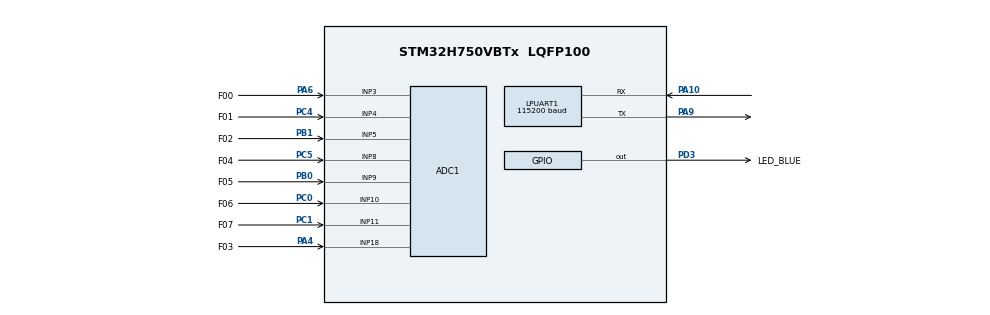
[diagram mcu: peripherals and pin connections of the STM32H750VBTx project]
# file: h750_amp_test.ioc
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ADC1.Channel-0\#ChannelRegularConversion=ADC_CHANNEL_3
ADC1.Channel-1\#ChannelRegularConversion=ADC_CHANNEL_4
ADC1.Channel-2\#ChannelRegularConversion=ADC_CHANNEL_5
ADC1.Channel-3\#ChannelRegularConversion=ADC_CHANNEL_8
ADC1.Channel-4\#ChannelRegularConversion=ADC_CHANNEL_9
ADC1.Channel-5\#ChannelRegularConversion=ADC_CHANNEL_10
ADC1.Channel-6\#ChannelRegularConversion=ADC_CHANNEL_11
ADC1.Channel-7\#ChannelRegularConversion=ADC_CHANNEL_18
ADC1.ClockPrescaler=ADC_CLOCK_ASYNC_DIV8
ADC1.ContinuousConvMode=ENABLE
ADC1.ConversionDataManagement=ADC_CONVERSIONDATA_DMA_CIRCULAR
ADC1.NbrOfConversion=8
ADC1.NbrOfConversionFlag=1
ADC1.OffsetNumber-0\#ChannelRegularConversion=ADC_OFFSET_NONE
ADC1.OffsetNumber-1\#ChannelRegularConversion=ADC_OFFSET_NONE
ADC1.OffsetNumber-2\#ChannelRegularConversion=ADC_OFFSET_NONE
ADC1.OffsetNumber-3\#ChannelRegularConversion=ADC_OFFSET_NONE
ADC1.OffsetNumber-4\#ChannelRegularConversion=ADC_OFFSET_NONE
ADC1.OffsetNumber-5\#ChannelRegularConversion=ADC_OFFSET_NONE
ADC1.OffsetNumber-6\#ChannelRegularConversion=ADC_OFFSET_NONE
ADC1.OffsetNumber-7\#ChannelRegularConversion=ADC_OFFSET_NONE
ADC1.OffsetSignedSaturation-0\#ChannelRegularConversion=DISABLE
ADC1.OffsetSignedSaturation-1\#ChannelRegularConversion=DISABLE
ADC1.OffsetSignedSaturation-2\#ChannelRegularConversion=DISABLE
ADC1.OffsetSignedSaturation-3\#ChannelRegularConversion=DISABLE
ADC1.OffsetSignedSaturation-4\#ChannelRegularConversion=DISABLE
ADC1.OffsetSignedSaturation-5\#ChannelRegularConversion=DISABLE
ADC1.OffsetSignedSaturation-6\#ChannelRegularConversion=DISABLE
ADC1.OffsetSignedSaturation-7\#ChannelRegularConversion=DISABLE
ADC1.Rank-0\#ChannelRegularConversion=1
ADC1.Rank-1\#ChannelRegularConversion=2
ADC1.Rank-2\#ChannelRegularConversion=3
ADC1.Rank-3\#ChannelRegularConversion=4
ADC1.Rank-4\#ChannelRegularConversion=5
ADC1.Rank-5\#ChannelRegularConversion=6
ADC1.Rank-6\#ChannelRegularConversion=7
ADC1.Rank-7\#ChannelRegularConversion=8
ADC1.SamplingTime-0\#ChannelRegularConversion=ADC_SAMPLETIME_32CYCLES_5
ADC1.SamplingTime-1\#ChannelRegularConversion=ADC_SAMPLETIME_32CYCLES_5
ADC1.SamplingTime-2\#ChannelRegularConversion=ADC_SAMPLETIME_32CYCLES_5
ADC1.SamplingTime-3\#ChannelRegularConversion=ADC_SAMPLETIME_32CYCLES_5
ADC1.SamplingTime-4\#ChannelRegularConversion=ADC_SAMPLETIME_32CYCLES_5
ADC1.SamplingTime-5\#ChannelRegularConversion=ADC_SAMPLETIME_32CYCLES_5
ADC1.SamplingTime-6\#ChannelRegularConversion=ADC_SAMPLETIME_32CYCLES_5
ADC1.SamplingTime-7\#ChannelRegularConversion=ADC_SAMPLETIME_32CYCLES_5
ADC1.master=1
Dma.ADC1.0.Direction=DMA_PERIPH_TO_MEMORY
Dma.ADC1.0.EventEnable=DISABLE
Dma.ADC1.0.FIFOMode=DMA_FIFOMODE_DISABLE
Dma.ADC1.0.Instance=DMA1_Stream0
Dma.ADC1.0.MemDataAlignment=DMA_MDATAALIGN_WORD
Dma.ADC1.0.MemInc=DMA_MINC_ENABLE
Dma.ADC1.0.Mode=DMA_CIRCULAR
Dma.ADC1.0.PeriphDataAlignment=DMA_PDATAALIGN_WORD
Dma.ADC1.0.PeriphInc=DMA_PINC_DISABLE
Dma.ADC1.0.Polarity=HAL_DMAMUX_REQ_GEN_RISING
Dma.ADC1.0.Priority=DMA_PRIORITY_LOW
Dma.ADC1.0.RequestNumber=1
Dma.ADC1.0.SignalID=NONE
Dma.ADC1.0.SyncEnable=DISABLE
Dma.ADC1.0.SyncPolarity=HAL_DMAMUX_SYNC_NO_EVENT
Dma.ADC1.0.SyncRequestNumber=1
Dma.ADC1.0.SyncSignalID=NONE
Dma.Request0=ADC1
LPUART1.BaudRate=115200
Mcu.Family=STM32H7
Mcu.Name=STM32H750VBTx
Mcu.Package=LQFP100
NVIC.ADC_IRQn=true\:0\:0\:false\:false\:true\:true\:true\:true
NVIC.DMA1_Stream0_IRQn=true\:0\:0\:false\:false\:true\:false\:true\:true
NVIC.PriorityGroup=NVIC_PRIORITYGROUP_4
PA10.Mode=Asynchronous
PA10.Signal=LPUART1_RX
PA13\ (JTMS/SWDIO).Mode=Serial_Wire
PA13\ (JTMS/SWDIO).Signal=DEBUG_JTMS-SWDIO
PA14\ (JTCK/SWCLK).Mode=Serial_Wire
PA14\ (JTCK/SWCLK).Signal=DEBUG_JTCK-SWCLK
PA4.GPIO_Label=F03
PA4.Signal=ADCx_INP18
PA6.GPIO_Label=F00
PA6.Signal=ADCx_INP3
PA9.Mode=Asynchronous
PA9.Signal=LPUART1_TX
PB0.GPIO_Label=F05
PB0.Signal=ADCx_INP9
PB1.GPIO_Label=F02
PB1.Signal=ADCx_INP5
PC0.GPIO_Label=F06
PC0.Signal=ADCx_INP10
PC1.GPIO_Label=F07
PC1.Signal=ADCx_INP11
PC14-OSC32_IN\ (OSC32_IN).Mode=LSE-External-Oscillator
PC14-OSC32_IN\ (OSC32_IN).Signal=RCC_OSC32_IN
PC15-OSC32_OUT\ (OSC32_OUT).Mode=LSE-External-Oscillator
PC15-OSC32_OUT\ (OSC32_OUT).Signal=RCC_OSC32_OUT
PC4.GPIO_Label=F01
PC4.Signal=ADCx_INP4
PC5.GPIO_Label=F04
PC5.Signal=ADCx_INP8
PD3.GPIO_Label=LED_BLUE
PD3.Signal=GPIO_Output
PH0-OSC_IN\ (PH0).Mode=HSE-External-Oscillator
PH0-OSC_IN\ (PH0).Signal=RCC_OSC_IN
PH1-OSC_OUT\ (PH1).Mode=HSE-External-Oscillator
PH1-OSC_OUT\ (PH1).Signal=RCC_OSC_OUT
ProjectManager.HeapSize=0x200
ProjectManager.StackSize=0x400
ProjectManager.TargetToolchain=STM32CubeIDE
RCC.ADCFreq_Value=50000000
RCC.APB1Freq_Value=50000000
RCC.APB2Freq_Value=50000000
RCC.APB3Freq_Value=50000000
RCC.APB4Freq_Value=50000000
RCC.CortexFreq_Value=400000000
RCC.D1PPRE=RCC_APB3_DIV2
RCC.D2PPRE1=RCC_APB1_DIV2
RCC.D2PPRE2=RCC_APB2_DIV2
RCC.D3PPRE=RCC_APB4_DIV2
RCC.DIVM1=5
RCC.DIVM2=25
RCC.DIVM3=25
RCC.DIVN1=160
RCC.DIVN2=200
RCC.DIVN3=200
RCC.DIVP2=4
RCC.HCLKFreq_Value=100000000
RCC.HPRE=RCC_HCLK_DIV4
RCC.PLLSourceVirtual=RCC_PLLSOURCE_HSE
RCC.SYSCLKFreq_VALUE=400000000
RCC.SYSCLKSource=RCC_SYSCLKSOURCE_PLLCLK
RCC.USBFreq_Value=400000000
SH.ADCx_INP10.0=ADC1_INP10,IN10-Single-Ended
SH.ADCx_INP11.0=ADC1_INP11,IN11-Single-Ended
SH.ADCx_INP18.0=ADC1_INP18,IN18-Single-Ended
SH.ADCx_INP3.0=ADC1_INP3,IN3-Single-Ended
SH.ADCx_INP4.0=ADC1_INP4,IN4-Single-Ended
SH.ADCx_INP5.0=ADC1_INP5,IN5-Single-Ended
SH.ADCx_INP8.0=ADC1_INP8,IN8-Single-Ended
SH.ADCx_INP9.0=ADC1_INP9,IN9-Single-Ended
board=custom

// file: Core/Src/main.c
/* USER CODE BEGIN Header */
/**
  ******************************************************************************
  * @file           : main.c
  * @brief          : Main program body
  ******************************************************************************
  * @attention
  *
  * Copyright (c) 2023 STMicroelectronics.
  * All rights reserved.
  *
  * This software is licensed under terms that can be found in the LICENSE file
  * in the root directory of this software component.
  * If no LICENSE file comes with this software, it is provided AS-IS.
  *
  ******************************************************************************
  */
/* USER CODE END Header */
#include "main.h"

ADC_HandleTypeDef hadc1;
DMA_HandleTypeDef hdma_adc1;

UART_HandleTypeDef hlpuart1;

/* USER CODE BEGIN PV */
uint32_t force_raw[8];
/* USER CODE END PV */

void SystemClock_Config(void);
static void MX_GPIO_Init(void);
static void MX_DMA_Init(void);
static void MX_LPUART1_UART_Init(void);
static void MX_ADC1_Init(void);

/* USER CODE BEGIN 0 */

void force_test(){
	float force[8];
	for(uint8_t i=0;i<8;++i){
		force[i]=(float)force_raw[i]*3.3/0xFFFF;
	}
	char msg[100]={0};
	sprintf(msg,"Force: %0.2f,%0.2f,%0.2f,%0.2f,%0.2f,%0.2f,%0.2f,%0.2f\n",force[0],force[1],force[2],force[3],force[4],force[5],force[6],force[7]);
	uint8_t i=0;
	while(msg[i]!=0 && i<100){
		HAL_UART_Transmit(&hlpuart1, (uint8_t*)(&msg[i++]), 1, 1);
	}
}

/* USER CODE END 0 */

int main(void)
{

  /* MCU Configuration--------------------------------------------------------*/

  /* Reset of all peripherals, Initializes the Flash interface and the Systick. */
  HAL_Init();

  /* Configure the system clock */
  SystemClock_Config();

  /* Initialize all configured peripherals */
  MX_GPIO_Init();
  MX_DMA_Init();
  MX_LPUART1_UART_Init();
  MX_ADC1_Init();
  /* USER CODE BEGIN 2 */

  HAL_ADC_Start_DMA(&hadc1,force_raw,8);

  /* USER CODE END 2 */

  /* Infinite loop */
  /* USER CODE BEGIN WHILE */
  while (1)
  {
	  force_test();
	  HAL_GPIO_TogglePin(LED_BLUE_GPIO_Port, LED_BLUE_Pin);
	  HAL_Delay(500);
    /* USER CODE END WHILE */

  }
}

void SystemClock_Config(void)
{
  RCC_OscInitTypeDef RCC_OscInitStruct = {0};
  RCC_ClkInitTypeDef RCC_ClkInitStruct = {0};

  /** Supply configuration update enable
  */
  HAL_PWREx_ConfigSupply(PWR_LDO_SUPPLY);

  /** Configure the main internal regulator output voltage
  */
  __HAL_PWR_VOLTAGESCALING_CONFIG(PWR_REGULATOR_VOLTAGE_SCALE1);

  while(!__HAL_PWR_GET_FLAG(PWR_FLAG_VOSRDY)) {}

  /** Initializes the RCC Oscillators according to the specified parameters
  * in the RCC_OscInitTypeDef structure.
  */
  RCC_OscInitStruct.OscillatorType = RCC_OSCILLATORTYPE_HSE;
  RCC_OscInitStruct.HSEState = RCC_HSE_ON;
  RCC_OscInitStruct.PLL.PLLState = RCC_PLL_ON;
  RCC_OscInitStruct.PLL.PLLSource = RCC_PLLSOURCE_HSE;
  RCC_OscInitStruct.PLL.PLLM = 5;
  RCC_OscInitStruct.PLL.PLLN = 160;
  RCC_OscInitStruct.PLL.PLLP = 2;
  RCC_OscInitStruct.PLL.PLLQ = 2;
  RCC_OscInitStruct.PLL.PLLR = 2;
  RCC_OscInitStruct.PLL.PLLRGE = RCC_PLL1VCIRANGE_2;
  RCC_OscInitStruct.PLL.PLLVCOSEL = RCC_PLL1VCOWIDE;
  RCC_OscInitStruct.PLL.PLLFRACN = 0;
  if (HAL_RCC_OscConfig(&RCC_OscInitStruct) != HAL_OK)
  {
    Error_Handler();
  }

  /** Initializes the CPU, AHB and APB buses clocks
  */
  RCC_ClkInitStruct.ClockType = RCC_CLOCKTYPE_HCLK|RCC_CLOCKTYPE_SYSCLK
                              |RCC_CLOCKTYPE_PCLK1|RCC_CLOCKTYPE_PCLK2
                              |RCC_CLOCKTYPE_D3PCLK1|RCC_CLOCKTYPE_D1PCLK1;
  RCC_ClkInitStruct.SYSCLKSource = RCC_SYSCLKSOURCE_PLLCLK;
  RCC_ClkInitStruct.SYSCLKDivider = RCC_SYSCLK_DIV1;
  RCC_ClkInitStruct.AHBCLKDivider = RCC_HCLK_DIV4;
  RCC_ClkInitStruct.APB3CLKDivider = RCC_APB3_DIV2;
  RCC_ClkInitStruct.APB1CLKDivider = RCC_APB1_DIV2;
  RCC_ClkInitStruct.APB2CLKDivider = RCC_APB2_DIV2;
  RCC_ClkInitStruct.APB4CLKDivider = RCC_APB4_DIV2;

  if (HAL_RCC_ClockConfig(&RCC_ClkInitStruct, FLASH_LATENCY_1) != HAL_OK)
  {
    Error_Handler();
  }
}

static void MX_ADC1_Init(void)
{

  ADC_MultiModeTypeDef multimode = {0};
  ADC_ChannelConfTypeDef sConfig = {0};

  /** Common config
  */
  hadc1.Instance = ADC1;
  hadc1.Init.ClockPrescaler = ADC_CLOCK_ASYNC_DIV8;
  hadc1.Init.Resolution = ADC_RESOLUTION_16B;
  hadc1.Init.ScanConvMode = ADC_SCAN_ENABLE;
  hadc1.Init.EOCSelection = ADC_EOC_SINGLE_CONV;
  hadc1.Init.LowPowerAutoWait = DISABLE;
  hadc1.Init.ContinuousConvMode = ENABLE;
  hadc1.Init.NbrOfConversion = 8;
  hadc1.Init.DiscontinuousConvMode = DISABLE;
  hadc1.Init.ExternalTrigConv = ADC_SOFTWARE_START;
  hadc1.Init.ExternalTrigConvEdge = ADC_EXTERNALTRIGCONVEDGE_NONE;
  hadc1.Init.ConversionDataManagement = ADC_CONVERSIONDATA_DMA_CIRCULAR;
  hadc1.Init.Overrun = ADC_OVR_DATA_PRESERVED;
  hadc1.Init.LeftBitShift = ADC_LEFTBITSHIFT_NONE;
  hadc1.Init.OversamplingMode = DISABLE;
  if (HAL_ADC_Init(&hadc1) != HAL_OK)
  {
    Error_Handler();
  }

  /** Configure the ADC multi-mode
  */
  multimode.Mode = ADC_MODE_INDEPENDENT;
  if (HAL_ADCEx_MultiModeConfigChannel(&hadc1, &multimode) != HAL_OK)
  {
    Error_Handler();
  }

  /** Configure Regular Channel
  */
  sConfig.Channel = ADC_CHANNEL_3;
  sConfig.Rank = ADC_REGULAR_RANK_1;
  sConfig.SamplingTime = ADC_SAMPLETIME_32CYCLES_5;
  sConfig.SingleDiff = ADC_SINGLE_ENDED;
  sConfig.OffsetNumber = ADC_OFFSET_NONE;
  sConfig.Offset = 0;
  sConfig.OffsetSignedSaturation = DISABLE;
  if (HAL_ADC_ConfigChannel(&hadc1, &sConfig) != HAL_OK)
  {
    Error_Handler();
  }

  /** Configure Regular Channel
  */
  sConfig.Channel = ADC_CHANNEL_4;
  sConfig.Rank = ADC_REGULAR_RANK_2;
  if (HAL_ADC_ConfigChannel(&hadc1, &sConfig) != HAL_OK)
  {
    Error_Handler();
  }

  /** Configure Regular Channel
  */
  sConfig.Channel = ADC_CHANNEL_5;
  sConfig.Rank = ADC_REGULAR_RANK_3;
  if (HAL_ADC_ConfigChannel(&hadc1, &sConfig) != HAL_OK)
  {
    Error_Handler();
  }

  /** Configure Regular Channel
  */
  sConfig.Channel = ADC_CHANNEL_8;
  sConfig.Rank = ADC_REGULAR_RANK_4;
  if (HAL_ADC_ConfigChannel(&hadc1, &sConfig) != HAL_OK)
  {
    Error_Handler();
  }

  /** Configure Regular Channel
  */
  sConfig.Channel = ADC_CHANNEL_9;
  sConfig.Rank = ADC_REGULAR_RANK_5;
  if (HAL_ADC_ConfigChannel(&hadc1, &sConfig) != HAL_OK)
  {
    Error_Handler();
  }

  /** Configure Regular Channel
  */
  sConfig.Channel = ADC_CHANNEL_10;
  sConfig.Rank = ADC_REGULAR_RANK_6;
  if (HAL_ADC_ConfigChannel(&hadc1, &sConfig) != HAL_OK)
  {
    Error_Handler();
  }

  /** Configure Regular Channel
  */
  sConfig.Channel = ADC_CHANNEL_11;
  sConfig.Rank = ADC_REGULAR_RANK_7;
  if (HAL_ADC_ConfigChannel(&hadc1, &sConfig) != HAL_OK)
  {
    Error_Handler();
  }

  /** Configure Regular Channel
  */
  sConfig.Channel = ADC_CHANNEL_18;
  sConfig.Rank = ADC_REGULAR_RANK_8;
  if (HAL_ADC_ConfigChannel(&hadc1, &sConfig) != HAL_OK)
  {
    Error_Handler();
  }

}

static void MX_LPUART1_UART_Init(void)
{

  hlpuart1.Instance = LPUART1;
  hlpuart1.Init.BaudRate = 115200;
  hlpuart1.Init.WordLength = UART_WORDLENGTH_8B;
  hlpuart1.Init.StopBits = UART_STOPBITS_1;
  hlpuart1.Init.Parity = UART_PARITY_NONE;
  hlpuart1.Init.Mode = UART_MODE_TX_RX;
  hlpuart1.Init.HwFlowCtl = UART_HWCONTROL_NONE;
  hlpuart1.Init.OneBitSampling = UART_ONE_BIT_SAMPLE_DISABLE;
  hlpuart1.Init.ClockPrescaler = UART_PRESCALER_DIV1;
  hlpuart1.AdvancedInit.AdvFeatureInit = UART_ADVFEATURE_NO_INIT;
  hlpuart1.FifoMode = UART_FIFOMODE_DISABLE;
  if (HAL_UART_Init(&hlpuart1) != HAL_OK)
  {
    Error_Handler();
  }
  if (HAL_UARTEx_SetTxFifoThreshold(&hlpuart1, UART_TXFIFO_THRESHOLD_1_8) != HAL_OK)
  {
    Error_Handler();
  }
  if (HAL_UARTEx_SetRxFifoThreshold(&hlpuart1, UART_RXFIFO_THRESHOLD_1_8) != HAL_OK)
  {
    Error_Handler();
  }
  if (HAL_UARTEx_DisableFifoMode(&hlpuart1) != HAL_OK)
  {
    Error_Handler();
  }

}

static void MX_DMA_Init(void)
{

  /* DMA controller clock enable */
  __HAL_RCC_DMA1_CLK_ENABLE();

  /* DMA interrupt init */
  /* DMA1_Stream0_IRQn interrupt configuration */
  HAL_NVIC_SetPriority(DMA1_Stream0_IRQn, 0, 0);
  HAL_NVIC_EnableIRQ(DMA1_Stream0_IRQn);

}

static void MX_GPIO_Init(void)
{
  GPIO_InitTypeDef GPIO_InitStruct = {0};

  /* GPIO Ports Clock Enable */
  __HAL_RCC_GPIOC_CLK_ENABLE();
  __HAL_RCC_GPIOH_CLK_ENABLE();
  __HAL_RCC_GPIOA_CLK_ENABLE();
  __HAL_RCC_GPIOB_CLK_ENABLE();
  __HAL_RCC_GPIOD_CLK_ENABLE();

  /*Configure GPIO pin Output Level */
  HAL_GPIO_WritePin(LED_BLUE_GPIO_Port, LED_BLUE_Pin, GPIO_PIN_RESET);

  /*Configure GPIO pin : LED_BLUE_Pin */
  GPIO_InitStruct.Pin = LED_BLUE_Pin;
  GPIO_InitStruct.Mode = GPIO_MODE_OUTPUT_PP;
  GPIO_InitStruct.Pull = GPIO_NOPULL;
  GPIO_InitStruct.Speed = GPIO_SPEED_FREQ_LOW;
  HAL_GPIO_Init(LED_BLUE_GPIO_Port, &GPIO_InitStruct);

}

void Error_Handler(void)
{
  __disable_irq();
  while (1)
  {
  }
}
